# nrf9120_modem register map
Vendor: Nordic Semiconductor; Series: nrf91; File version: 1
CPU: CM4 r0p1, little endian, MPU, FPU, 3 interrupt priority bits
Registers are 32-bit, read-write, reset 0x0 unless marked. A register's access mark holds for its fields unless they carry their own. Offsets are from the block's base; [hi:lo] are bit positions; {n}, {i} and the like mark numbered series.

## NVMC_NS — Non Volatile Memory Controller
Base 0x40060000; alternate view of ACL_NS
0x400 READY ro — Ready flag
  [0] READY — NVMC is ready or busy
    0=Busy (NVMC is busy (on-going write or erase operation)); 1=Ready (NVMC is ready)
0x404 READYNEXT ro — Ready flag
  [0] READYNEXT — NVMC can accept a new write operation
    0=Busy (NVMC cannot accept any write operation); 1=Ready (NVMC is ready)
0x504 CONFIG — Configuration register
  [2:0] WEN — Program memory access mode. It is strongly recommended to only activate erase and write modes when they are actively used. Enabling write or erase will invalidate the cache and keep it invalidated.
    0=Ren (Read only access); 1=Wen (Write enabled); 2=Een (Erase enabled); 4=PEen (Partial Erase enabled)
0x50C ERASEALL — Register for erasing all non-volatile user memory
  [0] ERASEALL — Erase all non-volatile memory including UICR registers. Note that the erase must be enabled using CONFIG.WEN before the non-volatile memory can be erased.
    0=NoOperation; 1=Erase (Start chip erase)
0x51C ERASEPAGEPARTIALCFG reset 0xA — Register for partial erase configuration
  [6:0] DURATION — Duration of the partial erase in milliseconds
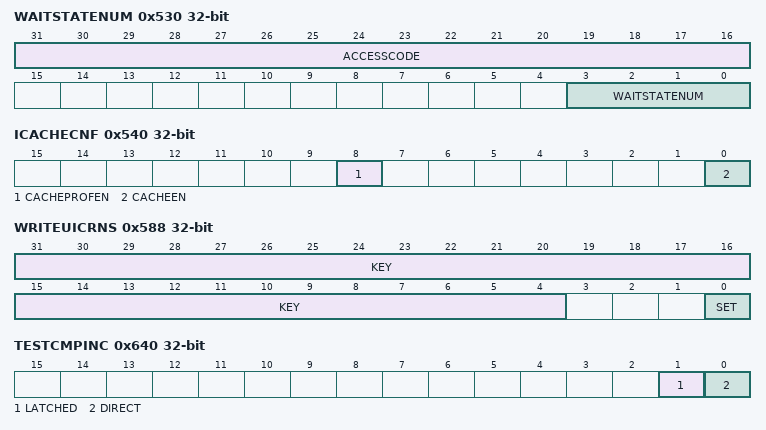
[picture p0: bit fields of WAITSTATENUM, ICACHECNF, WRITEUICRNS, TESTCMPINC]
0x530 WAITSTATENUM — Register to set the number of waitstate for flash access To update the WAITSTATENUM field, the ACCESSCODE must be correct.
  [31:16] ACCESSCODE — Access code for modifying this register
  [3:0] WAITSTATENUM — Flash wait states
0x540 ICACHECNF — I-code cache configuration register.
  [8] CACHEPROFEN — Cache profiling enable
    0=Disabled (Disable cache profiling); 1=Enabled (Enable cache profiling)
  [0] CACHEEN — Cache enable
    0=Disabled (Disable cache. Invalidates all cache entries.); 1=Enabled (Enable cache)
0x548 IHIT — I-code cache hit counter.
  [31:0] HITS — Number of cache hits
0x54C IMISS — I-code cache miss counter.
  [31:0] MISSES — Number of cache misses
0x584 CONFIGNS — Non SecureConfiguration register
  [1:0] WEN — Program memory access mode. It is strongly recommended to only activate erase and write modes when they are actively used. Enabling write or erase will invalidate the cache and keep it invalidated.
    0=Ren (Read only access); 1=Wen (Write enabled); 2=Een (Erase enabled)
0x588 WRITEUICRNS — Non Secure APPROTECT enable register
  [31:4] KEY — Key to write in order to valid the write operation
    0xAFBE5A7=Keyvalid (Key value)
  [0] SET — Allow non secure to set APPROTECT
    1=Set (Set value)
0x600 TESTMODE — Register for entering test mode. Refer to the flash IP test documentation for more details.
  [15:0] TESTMODE — Register for entering test mode. Refer to the flash IP test documentation for more details. This register does not return the same value as written.
    on read: 0=NORMAL (Read: Not in test-mode.); 1=Read: In test-mode 1; 2=Read: In test-mode 2; 4=Read: In test-mode 3 | on write: 0=SetNORMAL (Write: Sets NORMAL mode.); 0xBCDE=SetTESTMODE1 (Write: Sets test-mode 1.); 0xABCD=SetTESTMODE2 (Write: Sets test-mode 2.); 0xCDEF=SetTESTMODE3 (Write: Sets test-mode 3.)
0x604 LVEN — Low voltage read mode
  [31:0] LVEN
    0=Disable low voltage read mode; 0x6005EA5E=Enable low voltage read mode
0x610 TESTMASSERASE wo — Self-timed mass-erase operation
  [1:0] TESTMASSERASE
    3=EVERYTHING (Erase everything (all information pages and main block)); 2=MAIN (Erase only the main block); 1=NOOPERATION1; 0=NOOPERATION0
0x614 TESTERASEREFCELL wo — Self-timed erase reference cell operation
  [0] TESTERASEREFCELL
    1=START (Start the erase reference cell operation); 0=NOOPERATION
0x618 TESTTC ro — Observe the TC output from the flash macro
  [12:0] TC — TC output
{0x620+4i} TESTDATA128[{i}] (i=0..3) — Description collection: Direct flash test data word n
  [31:0] TESTDATA — Returns data out from flash when reading. Sets flash data in when writing.
{0x630+4i} TESTDATA128INC[{i}] (i=0..3) ro — Description collection: Direct flash test data word n. Post-increments TESTCONTROLADDR
  [31:0] TESTDATA — Returns data out from flash when reading. Use TESTDATA128[3:0] registers to set the compared data. Post-increments TESTCONTROLADDR. If TESTCONTROLLINES.SE is high, the read starts by pulsing the SE line low for Tnws. If TESTCONTROLLINES.SE is low, SE remains low for the whole access.
0x640 TESTCMPINC ro — Reads and compares last flash row to TESTDATA128 content. Post-increments TESTCONTROLADDR.
  [1] LATCHED — Reads and compares last flash row (latched lines) to TESTDATA128 content. Post-increments TESTCONTROLADDR. If TESTCONTROLLINES.SE is high, the read starts by pulsing the SE line low for Tnws. If TESTCONTROLLINES.SE is low, SE remains low for the whole access.
    0=Equal (Latched TESTDATA128 content and flash row read are equal); 1=NotEqual (Latched TESTDATA128 content and flash row read are different)
  [0] DIRECT — Reads and compares last flash row (direct lines) to TESTDATA128 content. Post-increments TESTCONTROLADDR. If TESTCONTROLLINES.SE is high, the read starts by pulsing the SE line low for Tnws. If TESTCONTROLLINES.SE is low, SE remains low for the whole access.
    0=Equal (Direct TESTDATA128 content and flash row read are equal); 1=NotEqual (Direct TESTDATA128 content and flash row read are different)
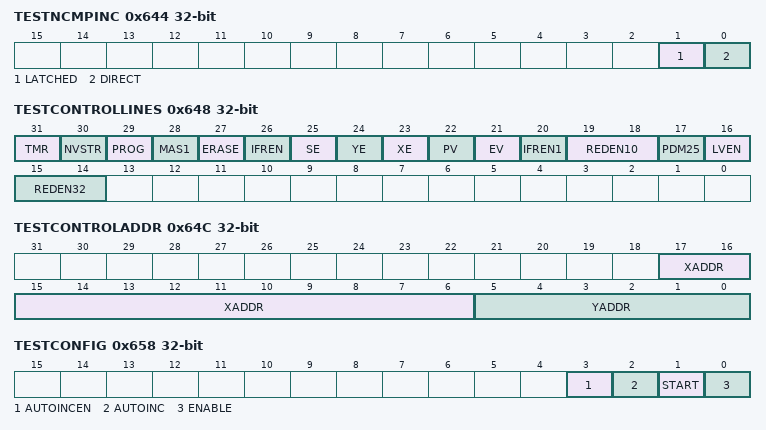
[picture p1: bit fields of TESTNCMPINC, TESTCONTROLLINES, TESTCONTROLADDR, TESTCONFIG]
0x644 TESTNCMPINC ro — Reads and compares last flash row to complement of TESTDATA128 content. Post-increments TESTCONTROLADDR.
  [1] LATCHED — Reads and compares last flash row (latched lines) to the complement of TESTDATA128 content (all bits inverted). Post-increments TESTCONTROLADDR. If TESTCONTROLLINES.SE is high, the read starts by pulsing the SE line low for Tnws. If TESTCONTROLLINES.SE is low, SE remains low for the whole access.
    0=Complement (Latched TESTDATA128 content and flash row read are each-other's complement); 1=NotComplement (Latched TESTDATA128 content and flash row read are not each-other's complement)
  [0] DIRECT — Reads and compares last flash row (direct lines) to the complement of TESTDATA128 content (all bits inverted). Post-increments TESTCONTROLADDR. If TESTCONTROLLINES.SE is high, the read starts by pulsing the SE line low for Tnws. If TESTCONTROLLINES.SE is low, SE remains low for the whole access.
    0=Complement (Direct TESTDATA128 content and flash row read are each-other's complement); 1=NotComplement (Direct TESTDATA128 content and flash row read are not each-other's complement)
0x648 TESTCONTROLLINES — Direct flash test, control lines. Refer to the flash IP test documentation for more details.
  [31] TMR — Control the TMR signal
  [30] NVSTR — Control the NVSTR signal
  [29] PROG — Control the PROG signal
  [28] MAS1 — Control the MAS1 signal
  [27] ERASE — Control the ERASE signal
  [26] IFREN — Control the IFREN signal
  [25] SE — Control the SE signal. This signal is delayed by hardware by Tas, so that it can be written simultaneously to XE and YE
  [24] YE — Control the YE signal
  [23] XE — Control the XE signal
  [22] PV — Control the PV signal
  [21] EV — Control the EV signal
  [20] IFREN1 — Control the IFREN1 signal
  [19:18] REDEN10 — Control the REDEN(1:0) signal
  [17] PDM25 — Control the PDM25 signal
  [16] LVEN — Control the LVEN signal
  [15:14] REDEN32 — Control the REDEN(3:2) signal
0x64C TESTCONTROLADDR — Direct flash test control, address lines
  [17:6] XADDR — Control the XADDR signal
  [5:0] YADDR — Control the YADDR signal
0x650 TESTCOUNTERRELOAD — Counter reload value, used when counting from SE or YE rising edge to latching of data
  [11:0] RELOAD — Counter reload value, in MCU bus cycles, used when counting from SE or YE rising edge to latching of data. Value of 0 has no effect (counter will not latch)
0x654 TESTCOUNTERRUNNING ro — Returns the state (counting or not) of the counter
  [0] RUNNING — Returns the state of the counter
    0=NotRunning (Counter is not running); 1=Running (Counter is running)
0x658 TESTCONFIG — Mode of operation of the counter
  [3] AUTOINCEN — Disables the address auto-increment or -decrement
    1=Disable (Address auto-incrementing/decrementing is disabled); 0=Enable (Address auto-incrementing/decrementing is enabled)
  [2] AUTOINC — Controls the address auto-increment or -decrement
    0=Increment (Address is auto-incrementing); 1=Decrement (Address is auto-decrementing)
  [1] START — Defines the starting point of the counter
    0=SE (Counter starts on SE rising edge); 1=YE (Counter starts on YE rising edge)
  [0] ENABLE — Returns the state of the counter
    0=Disabled (Counter is disabled); 1=Enabled (Counter is enabled)
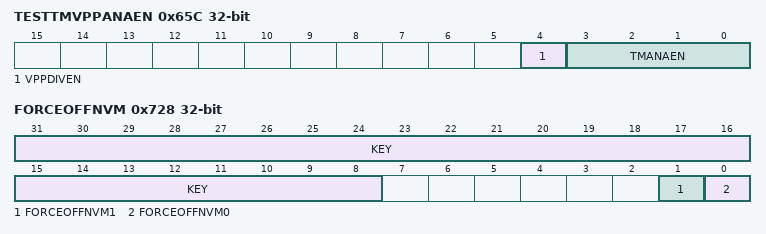
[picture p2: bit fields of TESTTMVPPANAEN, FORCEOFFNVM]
0x65C TESTTMVPPANAEN — Controls analog signals for flash measurements
  [4] VPPDIVEN — Enable the VPPDIV pad. Needs to be set when measuring VPPDIV on GPIO26 (P0.20), and when applying high-voltage on VPP pad.
    0=Disabled (VPPDIV pad disabled); 1=Enabled (VPPDIV pad enabled)
  [3:0] TMANAEN — Analog enable for TM measurement. Needs to be set when measuring TM[3:0] on P0.05, P0.04, P0.01 and P0.00.
    0=Disabled (All pads disabled); 15=Enabled (All pads enabled)
0x700 FORCEONNVM — Force on all NVM supplies. See also the internal section in the NVMC chapter.
  [0] FORCEONNVM
    0=Do not force on NVM supply; 1=Force on NVM supply
0x728 FORCEOFFNVM — Force off NVM supply. See also the internal section in the NVMC chapter.
  [31:8] KEY
    on write: 0xACCE55=EnableWrite (Must be written in order to write to bits 0-7. Any other value will ignore writes to this register. Read as zero.)
  [1] FORCEOFFNVM1 — Force off NVM supply 1. See also the internal section in the NVMC chapter.
    0=Do not force off supply; 1=Force off supply
  [0] FORCEOFFNVM0 — Force off NVM supply 0. See also the internal section in the NVMC chapter.
    0=Do not force off supply; 1=Force off supply
